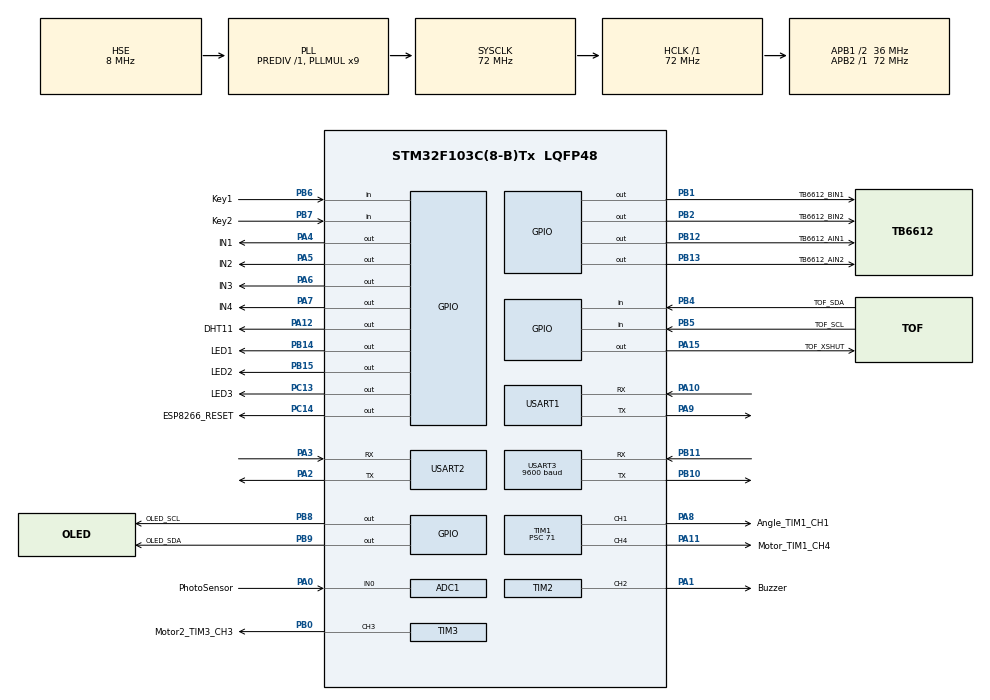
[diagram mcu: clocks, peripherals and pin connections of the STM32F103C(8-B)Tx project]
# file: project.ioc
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ADC1.Channel-16\#ChannelRegularConversion=ADC_CHANNEL_0
ADC1.NbrOfConversionFlag=1
ADC1.Rank-16\#ChannelRegularConversion=1
ADC1.SamplingTime-16\#ChannelRegularConversion=ADC_SAMPLETIME_1CYCLE_5
ADC1.master=1
Mcu.Family=STM32F1
Mcu.Name=STM32F103C(8-B)Tx
Mcu.Package=LQFP48
NVIC.PriorityGroup=NVIC_PRIORITYGROUP_4
NVIC.TIM4_IRQn=true\:1\:0\:true\:false\:true\:false\:true\:true
NVIC.TimeBase=TIM4_IRQn
NVIC.TimeBaseIP=TIM4
NVIC.USART2_IRQn=true\:0\:0\:false\:false\:true\:true\:true\:true
NVIC.USART3_IRQn=true\:0\:0\:false\:false\:true\:true\:true\:true
PA0-WKUP.GPIO_Label=PhotoSensor
PA0-WKUP.Signal=ADCx_IN0
PA1.GPIO_Label=Buzzer
PA1.GPIO_Speed=GPIO_SPEED_FREQ_HIGH
PA1.Signal=S_TIM2_CH2
PA10.Mode=Asynchronous
PA10.Signal=USART1_RX
PA11.GPIO_Label=Motor_TIM1_CH4
PA11.Signal=S_TIM1_CH4
PA12.GPIO_Label=DHT11
PA12.Signal=GPIO_Output
PA13.Mode=Serial_Wire
PA13.Signal=SYS_JTMS-SWDIO
PA14.Mode=Serial_Wire
PA14.Signal=SYS_JTCK-SWCLK
PA15.GPIO_Label=TOF_XSHUT
PA15.PinState=GPIO_PIN_SET
PA15.Signal=GPIO_Output
PA2.Mode=Asynchronous
PA2.Signal=USART2_TX
PA3.Mode=Asynchronous
PA3.Signal=USART2_RX
PA4.GPIO_Label=IN1
PA4.GPIO_ModeDefaultOutputPP=GPIO_MODE_OUTPUT_PP
PA4.GPIO_PuPd=GPIO_NOPULL
PA4.GPIO_Speed=GPIO_SPEED_FREQ_HIGH
PA4.PinState=GPIO_PIN_RESET
PA4.Signal=GPIO_Output
PA5.GPIO_Label=IN2
PA5.GPIO_ModeDefaultOutputPP=GPIO_MODE_OUTPUT_PP
PA5.GPIO_PuPd=GPIO_NOPULL
PA5.GPIO_Speed=GPIO_SPEED_FREQ_HIGH
PA5.PinState=GPIO_PIN_RESET
PA5.Signal=GPIO_Output
PA6.GPIO_Label=IN3
PA6.GPIO_ModeDefaultOutputPP=GPIO_MODE_OUTPUT_PP
PA6.GPIO_PuPd=GPIO_NOPULL
PA6.GPIO_Speed=GPIO_SPEED_FREQ_HIGH
PA6.PinState=GPIO_PIN_RESET
PA6.Signal=GPIO_Output
PA7.GPIO_Label=IN4
PA7.GPIO_ModeDefaultOutputPP=GPIO_MODE_OUTPUT_PP
PA7.GPIO_PuPd=GPIO_NOPULL
PA7.GPIO_Speed=GPIO_SPEED_FREQ_HIGH
PA7.PinState=GPIO_PIN_RESET
PA7.Signal=GPIO_Output
PA8.GPIO_Label=Angle_TIM1_CH1
PA8.Signal=S_TIM1_CH1
PA9.Mode=Asynchronous
PA9.Signal=USART1_TX
PB0.GPIO_Label=Motor2_TIM3_CH3
PB0.Signal=S_TIM3_CH3
PB1.GPIO_Label=TB6612_BIN1
PB1.Signal=GPIO_Output
PB10.Mode=Asynchronous
PB10.Signal=USART3_TX
PB11.Mode=Asynchronous
PB11.Signal=USART3_RX
PB12.GPIO_Label=TB6612_AIN1
PB12.Signal=GPIO_Output
PB13.GPIO_Label=TB6612_AIN2
PB13.Signal=GPIO_Output
PB14.GPIO_Label=LED1
PB14.PinState=GPIO_PIN_SET
PB14.Signal=GPIO_Output
PB15.GPIO_Label=LED2
PB15.PinState=GPIO_PIN_SET
PB15.Signal=GPIO_Output
PB2.GPIO_Label=TB6612_BIN2
PB2.Signal=GPIO_Output
PB4.GPIO_Label=TOF_SDA
PB4.Signal=GPIO_Input
PB5.GPIO_Label=TOF_SCL
PB5.Signal=GPIO_Input
PB6.GPIO_Label=Key1
PB6.Signal=GPIO_Input
PB7.GPIO_Label=Key2
PB7.Signal=GPIO_Input
PB8.GPIO_Label=OLED_SCL
PB8.GPIO_ModeDefaultOutputPP=GPIO_MODE_OUTPUT_OD
PB8.GPIO_PuPd=GPIO_PULLUP
PB8.PinState=GPIO_PIN_SET
PB8.Signal=GPIO_Output
PB9.GPIO_Label=OLED_SDA
PB9.GPIO_ModeDefaultOutputPP=GPIO_MODE_OUTPUT_OD
PB9.GPIO_PuPd=GPIO_PULLUP
PB9.PinState=GPIO_PIN_SET
PB9.Signal=GPIO_Output
PC13-TAMPER-RTC.GPIO_Label=LED3
PC13-TAMPER-RTC.PinState=GPIO_PIN_SET
PC13-TAMPER-RTC.Signal=GPIO_Output
PC14-OSC32_IN.GPIO_Label=ESP8266_RESET
PC14-OSC32_IN.Signal=GPIO_Output
PD0-OSC_IN.Mode=HSE-External-Oscillator
PD0-OSC_IN.Signal=RCC_OSC_IN
PD1-OSC_OUT.Mode=HSE-External-Oscillator
PD1-OSC_OUT.Signal=RCC_OSC_OUT
ProjectManager.HeapSize=0x200
ProjectManager.StackSize=0x400
ProjectManager.TargetToolchain=MDK-ARM V5.32
RCC.ADCPresc=RCC_ADCPCLK2_DIV6
RCC.AHBFreq_Value=72000000
RCC.APB1CLKDivider=RCC_HCLK_DIV2
RCC.APB1Freq_Value=36000000
RCC.APB1TimFreq_Value=72000000
RCC.APB2Freq_Value=72000000
RCC.APB2TimFreq_Value=72000000
RCC.HCLKFreq_Value=72000000
RCC.PLLMUL=RCC_PLL_MUL9
RCC.PLLSourceVirtual=RCC_PLLSOURCE_HSE
RCC.SYSCLKFreq_VALUE=72000000
RCC.SYSCLKSource=RCC_SYSCLKSOURCE_PLLCLK
RCC.USBFreq_Value=72000000
SH.ADCx_IN0.0=ADC1_IN0,IN0
SH.S_TIM1_CH1.0=TIM1_CH1,PWM Generation1 CH1
SH.S_TIM1_CH4.0=TIM1_CH4,PWM Generation4 CH4
SH.S_TIM2_CH2.0=TIM2_CH2,PWM Generation2 CH2
SH.S_TIM3_CH3.0=TIM3_CH3,PWM Generation3 CH3
TIM1.Channel-PWM\ Generation1\ CH1=TIM_CHANNEL_1
TIM1.Channel-PWM\ Generation4\ CH4=TIM_CHANNEL_4
TIM1.Period=20000
TIM1.Prescaler=71
TIM1.TIM_MasterOutputTrigger=TIM_TRGO_RESET
TIM2.Channel-PWM\ Generation2\ CH2=TIM_CHANNEL_2
TIM2.OCPolarity_2=TIM_OCPOLARITY_LOW
TIM2.Prescaler=0
TIM3.Channel-PWM\ Generation3\ CH3=TIM_CHANNEL_3
TIM3.Period=999
TIM3.Prescaler=71
USART1.VirtualMode=VM_ASYNC
USART2.VirtualMode=VM_ASYNC
USART3.BaudRate=9600
USART3.VirtualMode=VM_ASYNC
VP_SYS_VS_tim4.Mode=TIM4
VP_TIM1_VS_ClockSourceINT.Mode=Internal
VP_TIM2_VS_ClockSourceINT.Mode=Internal
VP_TIM3_VS_ClockSourceINT.Mode=Internal
board=custom

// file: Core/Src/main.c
/* USER CODE BEGIN Header */
/**
  ******************************************************************************
  * @file           : main.c
  * @brief          : Main program body
  ******************************************************************************
  * @attention
  *
  * Copyright (c) 2025 STMicroelectronics.
  * All rights reserved.
  *
  * This software is licensed under terms that can be found in the LICENSE file
  * in the root directory of this software component.
  * If no LICENSE file comes with this software, it is provided AS-IS.
  *
  ******************************************************************************
  */
/* USER CODE END Header */
#include "main.h"
#include "adc.h"
#include "tim.h"
#include "usart.h"
#include "gpio.h"

/* USER CODE BEGIN Includes */
#include "Scheduler.h"
extern u8 SNR_Buff[50];
/* USER CODE END Includes */

/* USER CODE BEGIN PTD */

int fputc( int ch, FILE *f)
{
	HAL_UART_Transmit(&huart1,(uint8_t*)&ch,1,HAL_MAX_DELAY);

	return ch;
}
/* USER CODE END PTD */

void SystemClock_Config(void);

int main(void)
{

  /* MCU Configuration--------------------------------------------------------*/

  /* Reset of all peripherals, Initializes the Flash interface and the Systick. */
  HAL_Init();

  /* Configure the system clock */
  SystemClock_Config();

  /* Initialize all configured peripherals */
  MX_GPIO_Init();
  MX_USART1_UART_Init();
  MX_ADC1_Init();
  MX_TIM1_Init();
  MX_USART2_UART_Init();
  MX_USART3_UART_Init();
  MX_TIM3_Init();
  MX_TIM2_Init();
  /* USER CODE BEGIN 2 */

		FreeRTOS_Start();

  /* USER CODE END 2 */

  /* Infinite loop */
  while (1)
  {

  }
}

void SystemClock_Config(void)
{
  RCC_OscInitTypeDef RCC_OscInitStruct = {0};
  RCC_ClkInitTypeDef RCC_ClkInitStruct = {0};
  RCC_PeriphCLKInitTypeDef PeriphClkInit = {0};

  /** Initializes the RCC Oscillators according to the specified parameters
  * in the RCC_OscInitTypeDef structure.
  */
  RCC_OscInitStruct.OscillatorType = RCC_OSCILLATORTYPE_HSE;
  RCC_OscInitStruct.HSEState = RCC_HSE_ON;
  RCC_OscInitStruct.HSEPredivValue = RCC_HSE_PREDIV_DIV1;
  RCC_OscInitStruct.HSIState = RCC_HSI_ON;
  RCC_OscInitStruct.PLL.PLLState = RCC_PLL_ON;
  RCC_OscInitStruct.PLL.PLLSource = RCC_PLLSOURCE_HSE;
  RCC_OscInitStruct.PLL.PLLMUL = RCC_PLL_MUL9;
  if (HAL_RCC_OscConfig(&RCC_OscInitStruct) != HAL_OK)
  {
    Error_Handler();
  }

  /** Initializes the CPU, AHB and APB buses clocks
  */
  RCC_ClkInitStruct.ClockType = RCC_CLOCKTYPE_HCLK|RCC_CLOCKTYPE_SYSCLK
                              |RCC_CLOCKTYPE_PCLK1|RCC_CLOCKTYPE_PCLK2;
  RCC_ClkInitStruct.SYSCLKSource = RCC_SYSCLKSOURCE_PLLCLK;
  RCC_ClkInitStruct.AHBCLKDivider = RCC_SYSCLK_DIV1;
  RCC_ClkInitStruct.APB1CLKDivider = RCC_HCLK_DIV2;
  RCC_ClkInitStruct.APB2CLKDivider = RCC_HCLK_DIV1;

  if (HAL_RCC_ClockConfig(&RCC_ClkInitStruct, FLASH_LATENCY_2) != HAL_OK)
  {
    Error_Handler();
  }
  PeriphClkInit.PeriphClockSelection = RCC_PERIPHCLK_ADC;
  PeriphClkInit.AdcClockSelection = RCC_ADCPCLK2_DIV6;
  if (HAL_RCCEx_PeriphCLKConfig(&PeriphClkInit) != HAL_OK)
  {
    Error_Handler();
  }
}

void HAL_TIM_PeriodElapsedCallback(TIM_HandleTypeDef *htim)
{
  if (htim->Instance == TIM4) {
    HAL_IncTick();
  }
}

void Error_Handler(void)
{
  __disable_irq();
  while (1)
  {
  }
}
